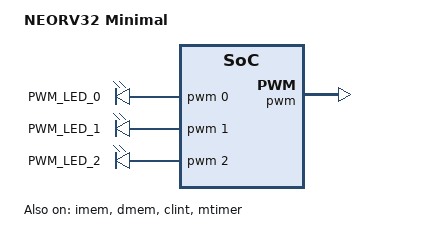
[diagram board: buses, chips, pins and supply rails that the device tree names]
/*
 * Copyright (c) 2025 Henrik Brix Andersen <henrik@brixandersen.dk>
 *
 * SPDX-License-Identifier: Apache-2.0
 */

/dts-v1/;

#include <neorv32.dtsi>
#include <mem.h>

/ {
	model = "NEORV32 Minimal";
	compatible = "neorv32";

	aliases {
		pwm-led0 = &pwm_led0;
		pwm-led1 = &pwm_led1;
		pwm-led2 = &pwm_led2;
	};

	chosen {
		zephyr,flash = &imem;
		zephyr,sram = &dmem;
	};

	pwmleds {
		compatible = "pwm-leds";

		pwm_led0: pwm_led0 {
			pwms = <&pwm 0 PWM_MSEC(20) PWM_POLARITY_NORMAL>;
			label = "PWM_LED_0";
		};

		pwm_led1: pwm_led1 {
			pwms = <&pwm 1 PWM_MSEC(20) PWM_POLARITY_NORMAL>;
			label = "PWM_LED_1";
		};

		pwm_led2: pwm_led2 {
			pwms = <&pwm 2 PWM_MSEC(20) PWM_POLARITY_NORMAL>;
			label = "PWM_LED_2";
		};
	};
};

&cpu0 {
	riscv,isa = "rv32ic_zicsr_zifencei";
};

&imem {
	status = "okay";
	reg = <0x0 DT_SIZE_K(8)>;
};

&dmem {
	status = "okay";
	reg = <0x80000000 DT_SIZE_K(64)>;
};

&clint {
	status = "okay";
};

&mtimer {
	status = "okay";
};

&pwm {
	status = "okay";
};
